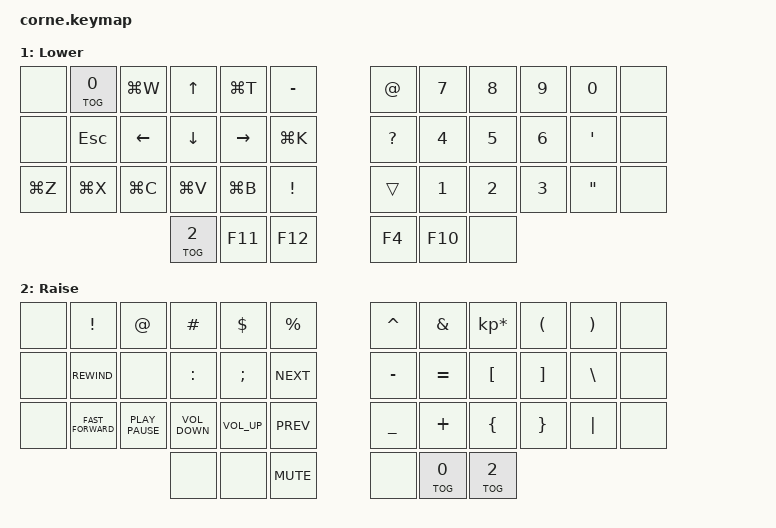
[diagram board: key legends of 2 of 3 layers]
/*
 * Copyright (c) 2020 The ZMK Contributors
 *
 * SPDX-License-Identifier: MIT
 */

#include <behaviors.dtsi>
#include <dt-bindings/zmk/keys.h>
#include <dt-bindings/zmk/bt.h>

/ {
        keymap {
                compatible = "zmk,keymap";

                default_layer {
// -----------------------------------------------------------------------------------------
// | NONE |  Q  |  W  |  F  |  P  |  B  |   |  J  |  L   |  U  |  Y  |  '  | NONE |
// | NONE |  A  |  S  |  R  |  T  |  G  |   |  M  |  N   |  E |  I  |  O  |  NONE |
// | NONE |  Z  |  X  |  C  |  D  |  V  |   |  K  | H   |  ,  |  .  |  /  | NONE |
//                    | LWR | SPC | SPC |   | ENT | RSE  | ALT |
                        label = "Base";
                        bindings = <
   &none   &kp Q &kp W &kp F &kp P &kp B   &kp J &kp L  &kp U     &kp Y   &kp SQT    &none
  &none LCTRL &kp A &kp S &kp R &kp T &kp G   &kp M &kp N  &kp E     &kp I   &kp O &none
   &none LSHFT &kp Z &kp X &kp C &kp D &kp V   &kp K &kp H  &kp COMMA &kp DOT &kp FSLH &none
                  &TOG 1 &kp SPACE &kp CAPS   &kp RET &kp BSPC &TOG 2
                        >;
                };
                lower_layer {
// -----------------------------------------------------------------------------------------
// | NONE | BASE |    |  UP  |  CMDT  |  -  |   |  @  |  7  |  8  |  9  |  0  |  NONE |
// | NONE|   ESC | LFT | DWN | RGT | CMDK |     | ?   |  4  |  5  | 6   |  '  |  NONE |
// | CMDZ | CMDX | CMDC | CMDV | CMDB |         | !   |  1  |  2  |  3  |  "  |  NONE |      
//                    | RAISE |  F11  | F12 |     | F4 | F10 | NONE |
                        label = "Lower";
                        bindings = <
   &none    &TOG 0    &kp LG(W)        &kp UP      &kp LG(T)       &kp MINUS         &kp AT   &kp N7   &kp N8 &kp N9    &kp N0 &none
   &none  &kp ESCAPE &kp LEFT &kp DOWN &kp RIGHT &kp LG(K)   &kp QUESTION &kp N4  &kp N5 &kp N6 &kp SQT &none
   &kp LG(Z)  &kp LG(X)   &kp LG(C)   &kp LG(V)   &kp LG(B)       &kp EXCL         &trans   &kp N1   &kp N2 &kp N3    &kp DQT &none
                          	        &TOG 2     &kp F11       &kp F12      &kp F4  &kp F10   &none
                        >;
                };

                raise_layer {
// -----------------------------------------------------------------------------------------
// | NONE |  !  |  @  |  #  |  $  |  %  |   |  ^  |  &  |  *  |  (  |  )  | NONE |
// | NONE |  RWD  | FWD |  :  |  ;  |NXT  |   |  -  |  =  |  [  |  ]  |  \  | NONE |
// | NONE | FF  |  PLAY  | VOLD |VOLU |PREV |   |  _  |  +  |  {  |  }  | "|" | NONE |
//                    | NONE | NONE | MUTE |   | NONE | BASE | RAISE |
                        label = "Raise";
                        bindings = <
    &none   &kp EXCL &kp AT &kp HASH &kp DLLR &kp PRCNT   &kp CARET &kp AMPS  &kp KP_MULTIPLY &kp LPAR &kp RPAR  &none 
    &none  &kp C_REWIND  &none &kp COLON   &kp SEMI   &kp  K_NEXT    &kp MINUS &kp EQUAL &kp LBKT        &kp RBKT &kp BSLH  &none 
    &none  &kp C_FAST_FORWARD  &kp K_PLAY_PAUSE  &kp K_VOLUME_DOWN  &kp K_VOLUME_UP   &kp  K_PREV      &kp UNDER &kp PLUS  &kp LBRC        &kp RBRC &kp PIPE  &none 
                    	     &none &none  &kp K_MUTE   &none   &TOG 0    &TOG 2 
                        >;
                };
        };
};
